AUTOSAR XML (schema 4-2-1)
package /ComponentTypes
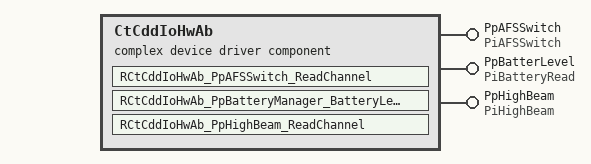
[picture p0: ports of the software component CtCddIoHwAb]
  complex device driver sw component type CtCddIoHwAb
    provide port PpAFSSwitch: server-com-spec{operation=ReadChannel, queue-length=1}, provided-interface=PiAFSSwitch
    provide port PpBatterLevel: server-com-spec{operation=ReadBatteryLevel, queue-length=1}, provided-interface=PiBatteryRead
    provide port PpHighBeam: server-com-spec{operation=ReadChannel, queue-length=1}, provided-interface=PiHighBeam
    behavior CtCddIoHwAb_InternalBehavior: data-type-mapping=ApMappingSet
      operation invoked event OIT_PpAFSSwitch_ReadChannel_PpAFSSwitch_ReadChannel: start-on-event=RCtCddIoHwAb_PpAFSSwitch_ReadChannel, operation=PpAFSSwitch.ReadChannel
      operation invoked event OIT_RCtCddIoHwAb_PpBatteryManager_BatteryLevel_PpBatterLevel_ReadBatteryLevel: start-on-event=RCtCddIoHwAb_PpBatteryManager_BatteryLevel, operation=PpBatterLevel.ReadBatteryLevel
      operation invoked event OIT_PiHighBeam_ReadChannel_PiHighBeam_ReadChannel: start-on-event=RCtCddIoHwAb_PpHighBeam_ReadChannel, operation=PpHighBeam.ReadChannel
      runnable RCtCddIoHwAb_PpAFSSwitch_ReadChannel
      runnable RCtCddIoHwAb_PpBatteryManager_BatteryLevel
      runnable RCtCddIoHwAb_PpHighBeam_ReadChannel
  swc implementation CtCddIoHwAb_Implementation: behavior=CtCddIoHwAb_InternalBehavior
    code-descriptors:
      code Default: artifact-descriptors=autosar-engineering-object={short-label=Default, category=SWSRC}
